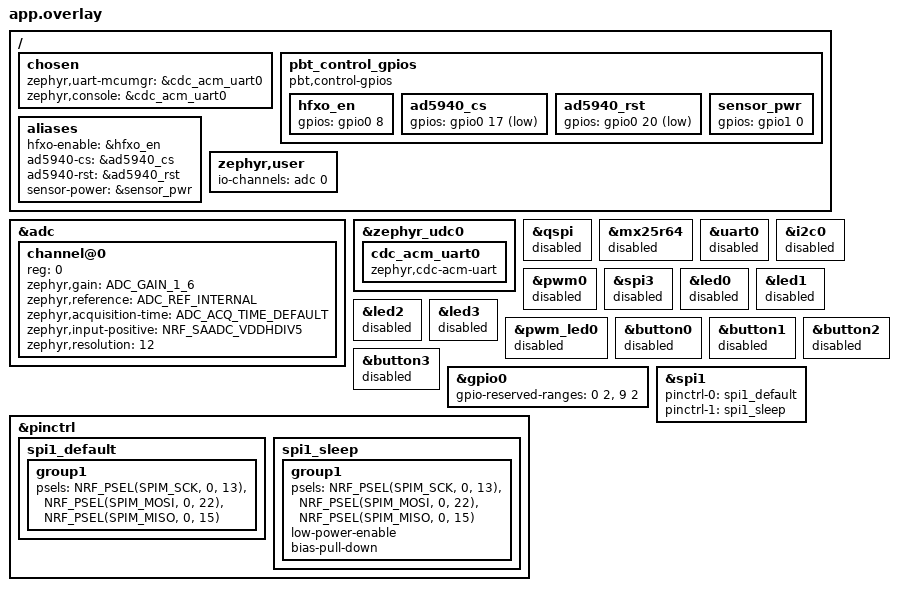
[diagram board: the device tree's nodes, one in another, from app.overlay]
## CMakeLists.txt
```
cmake_minimum_required(VERSION 3.20.0)
find_package(Zephyr REQUIRED HINTS $ENV{ZEPHYR_BASE})
project(nfc_ble_auth)

target_sources(app PRIVATE
    src/main.c
    src/nfc_handler.c
    src/ble_manager.c
    src/gatt_service.c
    src/power_manager.c
    src/ad5940.c
    src/ad5940_port.c
    src/RampTest.c
    src/CV.c
    src/ad5940_lp.c
    src/CA.c
    src/DPV.c
)
target_include_directories(app PRIVATE src)
# CHIPSEL_594X sélectionne les chemins de code AD5940 (pas ADuCM355)
target_compile_definitions(app PRIVATE CHIPSEL_594X)
```

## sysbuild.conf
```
# Active MCUboot via sysbuild
SB_CONFIG_BOOTLOADER_MCUBOOT=y
```

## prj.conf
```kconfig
# ── Bluetooth ─────────────────────────────────────────────────────────────
CONFIG_BT=y
CONFIG_BT_PERIPHERAL=y
CONFIG_BT_DEVICE_NAME="NFC_AUTH_DK"
CONFIG_BT_SMP=y
CONFIG_BT_SMP_SC_PAIR_ONLY=y
CONFIG_BT_CTLR_SDC_LLPM=n   
CONFIG_BT_BONDABLE=y
CONFIG_BT_SETTINGS=y
CONFIG_BT_MAX_PAIRED=1
CONFIG_BT_MAX_CONN=1

# ── Horloge basse fréquence de la carte ───────────────────────────────────
# U5 est un OV-7604-C7 actif (sortie CMOS 32,768 kHz, ±20 ppm) connecté à XL1,
# et non un quartz entre XL1/XL2. Le mode XTAL hérité de la cible DK est faux.
CONFIG_CLOCK_CONTROL_NRF_K32SRC_EXT_FULL_SWING=y
CONFIG_CLOCK_CONTROL_NRF_K32SRC_20PPM=y

# ── NFC T2T (pas T4T — le code utilise nfc_t2t_lib.h) ────────────────────
CONFIG_NFC_T2T_NRFXLIB=y          # ← T2T, pas T4T
CONFIG_NFC_NDEF=y
CONFIG_NFC_NDEF_MSG=y
CONFIG_NFC_NDEF_RECORD=y
CONFIG_NFC_NDEF_LE_OOB_REC=y

# ── Flash + NVS ───────────────────────────────────────────────────────────
# Le driver Flash interne nRF doit être activé en premier
CONFIG_FLASH=y
CONFIG_SOC_FLASH_NRF=y             # ← active le driver Flash nRF52840
CONFIG_FLASH_PAGE_LAYOUT=y         # dépend de SOC_FLASH_NRF → OK maintenant
CONFIG_FLASH_MAP=y
CONFIG_NVS=y
CONFIG_SETTINGS=y
CONFIG_SETTINGS_NVS=y              # backend NVS pour les settings BLE (liaisons)

# ── Logging ───────────────────────────────────────────────────────────────
CONFIG_LOG=y
CONFIG_LOG_DEFAULT_LEVEL=3

# ── Gestion d'alimentation ────────────────────────────────────────────────
# Pas de CONFIG_PM=y : HAS_PM n'est pas sélectionné pour nRF52840 en Zephyr 4.x.
# Le scheduler Zephyr fait automatiquement WFI (System ON sleep) quand inactif —
# comportement identique à ce qu'on cherche.

# ── ADC (SAADC) pour lecture du rail VDDH/VDD ───────────────────────────
CONFIG_ADC=y

# ── SPI (AD5940) ──────────────────────────────────────────────────────────
CONFIG_SPI=y
CONFIG_PINCTRL=y
CONFIG_PM_DEVICE=y

# MCUboot
CONFIG_BOOTLOADER_MCUBOOT=y
CONFIG_MCUBOOT_IMG_MANAGER=y

# USB (API NCS 3.x)
CONFIG_USB_DEVICE_STACK_NEXT=y
CONFIG_UART_LINE_CTRL=y

# mcumgr core + dépendances complètes
CONFIG_MCUMGR=y
CONFIG_NET_BUF=y
CONFIG_ZCBOR=y
CONFIG_CRC=y
CONFIG_BASE64=y

# mcumgr groups (noms NCS 3.x)
CONFIG_MCUMGR_GRP_OS=y
CONFIG_MCUMGR_GRP_IMG=y

CONFIG_MCUMGR_TRANSPORT_UDP=n
CONFIG_USBD_CDC_ACM_CLASS=y
# DFU USB mcumgr sur le port CDC. Le pilotage CV passe par un groupe SMP custom
# sur CE MÊME canal (multiplexé par mcumgr) → 1 seul port, pas de conflit.
CONFIG_MCUMGR_TRANSPORT_UART=y
CONFIG_UART_LINE_CTRL=y

# Le canal SMP doit rester PROPRE : on ne met AUCUN texte console/log sur l'UART
# (ça corromprait les trames SMP). Console + logs partent sur RTT (J-Link).
CONFIG_UART_CONSOLE=n
CONFIG_LOG_BACKEND_UART=n

# Pool de buffers du contrôleur USB : 1024 o (défaut) trop petit (échec
# "udc: Failed to allocate net_buf"). On l'agrandit.
CONFIG_UDC_BUF_POOL_SIZE=16384
CONFIG_UDC_BUF_COUNT=32

CONFIG_REBOOT=y

CONFIG_USE_SEGGER_RTT=y
CONFIG_RTT_CONSOLE=y
CONFIG_LOG_BACKEND_RTT=y

# Image manager + dépendances explicites
CONFIG_STREAM_FLASH=y
CONFIG_FLASH_MAP=y
CONFIG_FLASH=y
CONFIG_IMG_MANAGER=y

CONFIG_MPU_ALLOW_FLASH_WRITE=y

CONFIG_MCUMGR_TRANSPORT_UART_ASYNC=n

CONFIG_MCUMGR_TRANSPORT_NETBUF_SIZE=4096
CONFIG_MCUMGR_TRANSPORT_WORKQUEUE_STACK_SIZE=8192
CONFIG_MCUMGR_TRANSPORT_NETBUF_COUNT=6
# STATUS contient un diagnostic détaillé directement dans la map principale ;
# DATA contient des listes. Dimensionner explicitement les sauvegardes zcbor.
CONFIG_MCUMGR_SMP_CBOR_MAX_MAIN_MAP_ENTRIES=77
CONFIG_MCUMGR_SMP_CBOR_MAX_ENCODING_LEVELS=1

# Une commande START de CV par défaut occupe 131 octets après encodage
# SMP-over-UART (base64 + marqueur). La valeur par défaut de 128 rejette donc
# la commande avant même l'appel du handler.
CONFIG_UART_MCUMGR_RX_BUF_SIZE=256
CONFIG_UART_MCUMGR_RX_BUF_COUNT=2
```

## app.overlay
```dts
#include <dt-bindings/adc/nrf-adc.h>

/ {
    chosen {
        zephyr,uart-mcumgr = &cdc_acm_uart0;
        zephyr,console     = &cdc_acm_uart0;
    };

    /*
     * GPIO P0.08 : OE de l'oscillateur actif 32 MHz OSC1 du nRF52840.
     * Il doit rester HIGH : USB/BLE peut demander HFCLK à tout instant ; le
     * forcer LOW fige le CPU/USBD alors que le port COM reste encore énuméré.
     * Référencé via l'alias "hfxo-enable" dans power_manager.c.
     */
    /* Nœud volontairement neutre : ces lignes sont des commandes de carte,
     * pas des LED. Elles ne doivent jamais être revendiquées par le pilote LED. */
    pbt_control_gpios {
        compatible = "pbt,control-gpios";
        hfxo_en: hfxo_en {
            gpios = <&gpio0 8 GPIO_ACTIVE_HIGH>;
        };
        /* AD5940 : CS P0.17 (actif bas), RST P0.20 (actif bas), alim P1.00 */
        ad5940_cs: ad5940_cs {
            gpios = <&gpio0 17 GPIO_ACTIVE_LOW>;
        };
        ad5940_rst: ad5940_rst {
            gpios = <&gpio0 20 GPIO_ACTIVE_LOW>;
        };
        sensor_pwr: sensor_pwr {
            gpios = <&gpio1 0 GPIO_ACTIVE_HIGH>;
        };
    };

    aliases {
        hfxo-enable  = &hfxo_en;
        ad5940-cs    = &ad5940_cs;
        ad5940-rst   = &ad5940_rst;
        sensor-power = &sensor_pwr;
    };

    /*
     * Canal ADC pour lecture du rail VDDH/VDD de cette carte.
     * Utilise VDDHDIV5 (entrée interne nRF52840 = VDDH/5) — aucun pin requis.
     */
    zephyr,user {
        io-channels = <&adc 0>;
    };
};

/* Canal logique SAADC 0 : entrée interne VDDHDIV5, aucun GPIO. */
&adc {
    status = "okay";
    #address-cells = <1>;
    #size-cells = <0>;

    channel@0 {
        reg = <0>;
        zephyr,gain             = "ADC_GAIN_1_6";
        zephyr,reference        = "ADC_REF_INTERNAL";
        zephyr,acquisition-time = <ADC_ACQ_TIME_DEFAULT>;
        zephyr,input-positive   = <NRF_SAADC_VDDHDIV5>; /* VDDH/5 interne — aucun pin requis */
        zephyr,resolution       = <12>;
    };
};

&zephyr_udc0 {
    status = "okay";
    /* Port unique SMP : DFU mcumgr + commandes/données de mesure. Logs sur RTT. */
    cdc_acm_uart0: cdc_acm_uart0 {
        compatible = "zephyr,cdc-acm-uart";
    };
};

/*
 * Le binaire utilise encore la cible Zephyr nrf52840dk/nrf52840, mais le PCB
 * PBT n'embarque aucun des périphériques Arduino/QSPI de la DK. Les laisser
 * actifs crée de vrais conflits de broches : le QSPI de la DK revendique
 * notamment P0.17/P0.20/P0.22 (CS/RESET/MOSI de l'AD5940) et l'UART0 P0.08
 * (commande de l'oscillateur externe). Le DFU passe par l'USB natif ci-dessus
 * et ne dépend d'aucun de ces blocs.
 */
&qspi  { status = "disabled"; };
&mx25r64 { status = "disabled"; };
&uart0 { status = "disabled"; };
&i2c0  { status = "disabled"; };
&pwm0  { status = "disabled"; };
&spi3  { status = "disabled"; };

/* Nœuds d'E/S purement DK : certains partagent SCLK/MISO de l'AD5940. */
&led0     { status = "disabled"; };
&led1     { status = "disabled"; };
&led2     { status = "disabled"; };
&led3     { status = "disabled"; };
&pwm_led0 { status = "disabled"; };
&button0  { status = "disabled"; };
&button1  { status = "disabled"; };
&button2  { status = "disabled"; };
&button3  { status = "disabled"; };

&gpio0 {
    /* Garder uniquement XL1/XL2 et NFC1/NFC2 réservés. */
    gpio-reserved-ranges = <0 2>, <9 2>;
};

/* ── SPI1 : AD5940 ──────────────────────────────────────────────────────── */
/* SCLK=P0.13  MOSI=P0.22  MISO=P0.15  CS=P0.17 (GPIO manuel, actif bas) */
&pinctrl {
    spi1_default: spi1_default {
        group1 {
            psels = <NRF_PSEL(SPIM_SCK,  0, 13)>,
                    <NRF_PSEL(SPIM_MOSI, 0, 22)>,
                    <NRF_PSEL(SPIM_MISO, 0, 15)>;
        };
    };
    spi1_sleep: spi1_sleep {
        group1 {
            psels = <NRF_PSEL(SPIM_SCK,  0, 13)>,
                    <NRF_PSEL(SPIM_MOSI, 0, 22)>,
                    <NRF_PSEL(SPIM_MISO, 0, 15)>;
            low-power-enable;
            bias-pull-down;
        };
    };
};

&spi1 {
    status = "okay";
    pinctrl-0 = <&spi1_default>;
    pinctrl-1 = <&spi1_sleep>;
    pinctrl-names = "default", "sleep";
};
```

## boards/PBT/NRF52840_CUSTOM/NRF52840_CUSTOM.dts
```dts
/dts-v1/;

#include <nordic/nrf52840_qiaa.dtsi>
#include "NRF52840_CUSTOM-pinctrl.dtsi"

/ {
	model = "PBT custom board";
	compatible = "PBT,NRF52840-CUSTOM";

	chosen {
		zephyr,sram = &sram0;
		zephyr,flash = &flash0;
		zephyr,code-partition = &slot0_partition;
	};
};

&flash0 {
	partitions {
		compatible = "fixed-partitions";
		#address-cells = <1>;
		#size-cells = <1>;

		boot_partition: partition@0 {
			label = "mcuboot";
			reg = <0x0 DT_SIZE_K(80)>;
		};

		slot0_partition: partition@14000 {
			label = "image-0";
			reg = <0x14000 DT_SIZE_K(456)>;
		};

		slot1_partition: partition@86000 {
			label = "image-1";
			reg = <0x86000 DT_SIZE_K(456)>;
		};

		storage_partition: partition@f8000 {
			label = "storage";
			reg = <0xf8000 DT_SIZE_K(32)>;
		};
	};
};
```

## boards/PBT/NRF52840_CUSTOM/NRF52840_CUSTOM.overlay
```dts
&zephyr_udc0 {
    status = "okay";
    cdc_acm_uart0: cdc_acm_uart0 {
        compatible = "zephyr,cdc-acm-uart";
    };
};
```

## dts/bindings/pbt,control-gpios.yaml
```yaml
description: GPIO command lines owned directly by the ParisBioTek application

compatible: "pbt,control-gpios"

child-binding:
  description: One application-owned GPIO command line

  properties:
    gpios:
      type: phandle-array
      required: true
```

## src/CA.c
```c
#include "CA.h"
#include "ad5940_lp.h"

#include <zephyr/kernel.h>
#include <zephyr/logging/log.h>
#include <math.h>

LOG_MODULE_REGISTER(ca, LOG_LEVEL_INF);

static ca_params_t s_p = {
    .pot_mv      = 500.0f,
    .vzero_mv    = 1300.0f,
    .duration_ms = 10000,
    .interval_ms = 100,
};
static cv_point_cb_t s_cb;
static int32_t       s_peak_na;

void CA_SetPointCallback(cv_point_cb_t cb) { s_cb = cb; }

void CA_GetParams(ca_params_t *out) { if (out) *out = s_p; }

int CA_SetParams(const ca_params_t *in)
{
    if (!in) return -1;
    if (!isfinite(in->pot_mv) || !isfinite(in->vzero_mv)) return -1;
    if (in->duration_ms < 100u  || in->duration_ms > 600000u) return -1;
    if (in->interval_ms < 5u    || in->interval_ms > 10000u)  return -1;
    if (in->interval_ms > in->duration_ms)                    return -1;
    if (in->duration_ms / in->interval_ms > CV_MAX_TOTAL_POINTS) return -1;
    if (lp_validate_potential_mv(in->vzero_mv, in->pot_mv) != 0) return -1;
    s_p = *in;
    LOG_INF("CA params : E=%d mV  Vzero=%d mV  durée=%u ms  intervalle=%u ms",
            (int)s_p.pot_mv, (int)s_p.vzero_mv,
            (unsigned)s_p.duration_ms, (unsigned)s_p.interval_ms);
    return 0;
}

int32_t CA_GetPeakCurrentNa(void) { return s_peak_na; }

static bool ca_wait_or_stop(uint32_t delay_ms, measurement_stop_cb_t stop_cb)
{
    while (delay_ms > 0u) {
        if (stop_cb && stop_cb()) return true;
        uint32_t slice_ms = (delay_ms > 20u) ? 20u : delay_ms;
        k_sleep(K_MSEC(slice_ms));
        delay_ms -= slice_ms;
    }
    return stop_cb && stop_cb();
}

int CA_Run(float lfosc_hz, uint32_t rtia_ohm,
           measurement_stop_cb_t stop_cb)
{
    ca_params_t p = s_p;
    s_peak_na = 0;

    if (stop_cb && stop_cb()) {
        return MEAS_RUN_STOPPED;
    }

    if (lp_setup(lfosc_hz, rtia_ohm) != 0) {
        return -1;
    }

    if (stop_cb && stop_cb()) {
        lp_teardown();
        return MEAS_RUN_STOPPED;
    }

    if (lp_set_potential_mv(p.vzero_mv, p.pot_mv) != 0) {
        lp_teardown();
        return -1;
    }
    if (ca_wait_or_stop(50u, stop_cb)) {     /* établissement de la cellule */
        lp_teardown();
        return MEAS_RUN_STOPPED;
    }

    uint32_t n = p.duration_ms / p.interval_ms;
    if (n == 0) n = 1;

    int64_t t0   = k_uptime_get();
    float   peak = 0.0f;

    for (uint32_t k = 0; k < n; k++) {
        int64_t target = t0 + (int64_t)k * p.interval_ms;
        int64_t now    = k_uptime_get();
        if (target > now) {
            if (ca_wait_or_stop((uint32_t)(target - now), stop_cb)) {
                s_peak_na = (int32_t)(peak * 1000.0f);
                lp_teardown();
                LOG_INF("CA interrompue par l'utilisateur apres %u point(s)",
                        (unsigned)k);
                return MEAS_RUN_STOPPED;
            }
        }
        if (stop_cb && stop_cb()) {
            s_peak_na = (int32_t)(peak * 1000.0f);
            lp_teardown();
            return MEAS_RUN_STOPPED;
        }
        float i_ua = lp_read_current_ua();
        if (!isfinite(i_ua)) {
            lp_teardown();
            return -1;
        }
        if (fabsf(i_ua) > peak) peak = fabsf(i_ua);

        uint32_t t_ms = (uint32_t)(k_uptime_get() - t0);
        if (s_cb) s_cb(k, (float)t_ms, i_ua);   /* X = temps (ms) */
    }

    s_peak_na = (int32_t)(peak * 1000.0f);
    lp_teardown();
    LOG_INF("CA terminée — %u points, pic=%d nA", (unsigned)n, s_peak_na);
    return 0;
}
```

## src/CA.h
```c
#ifndef CA_H_
#define CA_H_

#include <stdint.h>
#include "ad5940.h"
#include "methods.h"
#include "CV.h"          /* cv_point_cb_t (callback commun aux méthodes) */

/* Chronoampérométrie (i–t) : potentiel fixe, courant échantillonné dans le temps.
 * Logiciel-timé (LPDAC + lectures ADC ponctuelles via ad5940_lp). X = temps (ms). */
typedef struct {
    float    pot_mv;       /* potentiel appliqué (mV, électrode de travail) */
    float    vzero_mv;     /* point de polarisation Vzero (mV)              */
    uint32_t duration_ms;  /* durée totale de la mesure (ms)                */
    uint32_t interval_ms;  /* période d'échantillonnage (ms)                */
} ca_params_t;

void    CA_SetPointCallback(cv_point_cb_t cb);
void    CA_GetParams(ca_params_t *out);
int     CA_SetParams(const ca_params_t *in);   /* 0 si OK, <0 si hors plage */

/* Lance la chronoampérométrie (bloquant). rtia_ohm = gamme (ohms, >0).
 * Retour : 0 si le run est complet, MEAS_RUN_STOPPED si l'utilisateur l'a
 * interrompu, valeur négative en cas d'erreur technique. */
int     CA_Run(float lfosc_hz, uint32_t rtia_ohm,
               measurement_stop_cb_t stop_cb);

/* Pic de courant absolu du dernier run (nA). */
int32_t CA_GetPeakCurrentNa(void);

#endif /* CA_H_ */
```

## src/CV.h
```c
#ifndef _CV_H_
#define _CV_H_

#include <stdint.h>
#include "ad5940.h"
#include "methods.h"

/* ═══════════════════════════════════════════════════════════════════════════
   PARAMÈTRES UTILISATEUR
   ═══════════════════════════════════════════════════════════════════════════ */
#define CV_START_VOLT_MV        -1000.0f
#define CV_PEAK_VOLT_MV         +1000.0f
#define CV_VZERO_MV              1300.0f

#define CV_STEP_NUMBER            800
#define CV_CYCLE_COUNT              1
#define CV_DURATION_MS          24000
#define CV_SAMPLE_DELAY_MS        7.0f
#define CV_SETTLE_MS              2000u
#define CV_SETTLE_MAX_MS         60000u

/* Must stay in sync with the point-transfer buffer in main.c. */
#define CV_MAX_TOTAL_POINTS       4000u

#define CV_RTIA_SEL             LPTIARTIA_4K
#define CV_ADC_PGA_GAIN         ADCPGA_1P5

#define CV_RCAL_OHM             100.0f
/* AD5940_ADCCode2Volt() attend des volts, pas des millivolts. */
#define CV_ADC_REF_V              1.820f

/* Forçage du RTIA en ohms : si > 0, la calibration RTIA est ignorée et cette
 * valeur est utilisée pour convertir le courant. À utiliser quand la
 * calibration (qui dépend de la RCAL externe = CV_RCAL_OHM) est fausse.
 * Mettre 0 pour calibrer normalement.
 * Valeur empirique mesurée avec une résistance étalon de 10 kΩ : ~4600 Ω. */
#define CV_RTIA_OVERRIDE_OHM    0

/* ═══════════════════════════════════════════════════════════════════════════
   API PUBLIQUE
   ═══════════════════════════════════════════════════════════════════════════ */

AD5940Err CV_Init(float lfosc_hz);
AD5940Err CV_Start(void);
/* Retourne immédiatement toute erreur ISR/séquenceur afin que l'appelant ne
 * transforme pas la cause initiale en simple timeout générique. */
AD5940Err CV_Service(void);
void      CV_Abort(void);
int       CV_IsFinished(void);
AD5940Err CV_Restart(void);

/* Courant de pic mesuré lors du dernier cycle, en nanoampères (nA).
 * Valeur absolue maximale parmi tous les points du cycle. */
int32_t CV_GetPeakCurrentNa(void);

/* Résistance estimée du dernier cycle (Ω), pente V/I par moindres carrés
 * passant par l'origine. Pertinent pour tester une simple résistance.
 * Retourne 0 si pas assez de points. */
float CV_GetResistanceOhm(void);

/* Callback appelé pour CHAQUE point traité pendant le cycle CV.
 * @param index       index de l'échantillon dans le cycle (0..StepNumber)
 * @param volt_mv     tension appliquée à cet échantillon (mV)
 * @param current_ua  courant mesuré (µA)
 */
typedef void (*cv_point_cb_t)(uint32_t index, float volt_mv, float current_ua);

/* Enregistre (ou retire avec NULL) le callback par point. */
void CV_SetPointCallback(cv_point_cb_t cb);

/* ═══════════════════════════════════════════════════════════════════════════
   PARAMÈTRES DE BALAYAGE RÉGLABLES AU RUNTIME
   Initialisés aux valeurs CV_* ci-dessus ; surchargeables via CV_SetParams()
   (commande "SET" reçue sur le serial). Les gains matériels (RTIA, PGA, RCAL,
   Vref ADC) restent fixes/calibrés et ne sont PAS exposés.
   ═══════════════════════════════════════════════════════════════════════════ */
typedef struct {
    float    start_mv;        /* tension de départ du balayage (mV)        */
    float    peak_mv;         /* tension de sommet du balayage (mV)        */
    float    vzero_mv;        /* tension de polarisation Vzero (mV)        */
    uint32_t step_number;     /* nombre de pas PAR cycle (pair, >= 2)      */
    uint32_t cycle_count;     /* nombre de cycles successifs (>= 1)        */
    uint32_t duration_ms;     /* durée d'UN cycle (ms)                     */
    float    sample_delay_ms; /* délai d'échantillon par pas (ms)          */
    uint32_t settle_ms;       /* maintien a start_mv avant le 1er point */
} cv_params_t;

/* Copie les paramètres courants (réglables) dans *out. */
void CV_GetParams(cv_params_t *out);

/* Valide puis applique de nouveaux paramètres. Retourne 0 si OK, <0 si une
 * valeur est hors plage (dans ce cas les paramètres ne sont pas modifiés).
 * La prise d'effet est au prochain CV_Init() : un cycle en cours n'est pas
 * perturbé. */
int CV_SetParams(const cv_params_t *in);

/* Durée totale (ms) du run EN COURS, tous cycles compris (instantané pris
 * au CV_Init), pour le timeout. La stabilisation initiale n'est pas incluse. */
uint32_t CV_GetActiveDurationMs(void);

/* Geometry of the run currently prepared by CV_Init(). `step_number` remains
 * the number of points in one elementary cycle. */
uint32_t CV_GetActiveStepNumber(void);
uint32_t CV_GetActiveCycleCount(void);
uint32_t CV_GetActiveTotalPoints(void);

/* ═══════════════════════════════════════════════════════════════════════════
   GAMME DE MESURE (RTIA) — réglable au runtime + autorange
   Le RTIA fixe la fenêtre de courant : I_max ≈ ~0,9 V / RTIA.
   ═══════════════════════════════════════════════════════════════════════════ */

/* Règle le RTIA (ohms) : la valeur de table la plus proche est retenue.
 * ohm == 0  → active l'autorange (choix automatique de la gamme).
 * Retourne l'ohm effectivement retenu (0 si autorange). */
int CV_SetRtia(uint32_t ohm);

/* RTIA nominal courant (ohms), ou 0 si autorange actif (pour le réglage). */
uint32_t CV_GetRtiaOhm(void);

/* RTIA nominal effectivement sélectionné (ohms), même en autorange (pour le
 * rapport après choix). */
uint32_t CV_GetActiveRtiaOhm(void);

/* 1 si l'autorange est actif, 0 sinon. */
int CV_GetAutorange(void);

/* RTIA réellement calibré au dernier CV_Init (ohms). */
uint32_t CV_GetCalibratedRtiaOhm(void);

/* Renvoie la sélection matérielle LPTIARTIA_* de la valeur de table la plus
 * proche de `ohm` ; *ohm_out (si non NULL) reçoit l'ohm nominal correspondant.
 * Utilisé par les autres méthodes (ad5940_lp) pour partager la même table RTIA. */
uint32_t CV_RtiaSelNearest(uint32_t ohm, uint32_t *ohm_out);

/* Sélection automatique de gamme : lance des balayages de sonde rapides pour
 * choisir le RTIA. À appeler après l'init AD5940 et AVANT le CV_Init du vrai
 * cycle. Ne fait rien si l'autorange n'est pas actif. */
int CV_Autorange(float lfosc_hz, measurement_stop_cb_t stop_cb);

/* Applique le potentiel initial directement au LPDAC apres CV_Init(), sans
 * lancer le WUPT ni produire d'echantillon. L'appelant maintient ensuite ce
 * potentiel pendant settle_ms avant CV_Start(). */
AD5940Err CV_ApplyStartPotential(void);

/* Stabilisation configuree pour le run fige par le dernier CV_Init(). */
uint32_t CV_GetActiveSettleMs(void);

#endif /* _CV_H_ */
```

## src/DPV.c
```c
#include "DPV.h"
#include "ad5940_lp.h"

#include <zephyr/kernel.h>
#include <zephyr/logging/log.h>
#include <math.h>

LOG_MODULE_REGISTER(dpv, LOG_LEVEL_INF);

static dpv_params_t s_p = {
    .start_mv   = -600.0f,
    .end_mv     =  600.0f,
    .estep_mv   =    5.0f,
    .epulse_mv  =   50.0f,
    .tpulse_ms  =   50,
    .tperiod_ms =  200,
    .vzero_mv   = 1300.0f,
};
static cv_point_cb_t s_cb;
static int32_t       s_peak_na;

void DPV_SetPointCallback(cv_point_cb_t cb) { s_cb = cb; }

void DPV_GetParams(dpv_params_t *out) { if (out) *out = s_p; }

int DPV_SetParams(const dpv_params_t *in)
{
    if (!in) return -1;
    if (!isfinite(in->start_mv) || !isfinite(in->end_mv) ||
        !isfinite(in->estep_mv) || !isfinite(in->epulse_mv) ||
        !isfinite(in->vzero_mv))                              return -1;
    if (in->end_mv == in->start_mv)                        return -1;
    if (in->estep_mv <= 0.0f || in->estep_mv > 200.0f)     return -1;
    if (in->epulse_mv == 0.0f || fabsf(in->epulse_mv) > 500.0f) return -1;
    if (in->tpulse_ms < 5u || in->tpulse_ms > 5000u)       return -1;
    if (in->tperiod_ms <= in->tpulse_ms || in->tperiod_ms > 20000u) return -1;
    if ((uint32_t)(fabsf(in->end_mv - in->start_mv) /
                   fabsf(in->estep_mv)) + 1u > CV_MAX_TOTAL_POINTS) return -1;
    if (lp_validate_potential_mv(in->vzero_mv, in->start_mv) != 0 ||
        lp_validate_potential_mv(in->vzero_mv, in->end_mv) != 0 ||
        lp_validate_potential_mv(in->vzero_mv, in->start_mv + in->epulse_mv) != 0 ||
        lp_validate_potential_mv(in->vzero_mv, in->end_mv + in->epulse_mv) != 0) return -1;
    s_p = *in;
    LOG_INF("DPV params : %d→%d mV  pas=%d  pulse=%d mV  tp=%u ms  T=%u ms",
            (int)s_p.start_mv, (int)s_p.end_mv, (int)s_p.estep_mv,
            (int)s_p.epulse_mv, (unsigned)s_p.tpulse_ms, (unsigned)s_p.tperiod_ms);
    return 0;
}

int32_t DPV_GetPeakCurrentNa(void) { return s_peak_na; }

static bool dpv_wait_or_stop(uint32_t delay_ms, measurement_stop_cb_t stop_cb)
{
    while (delay_ms > 0u) {
        if (stop_cb && stop_cb()) return true;
        uint32_t slice_ms = (delay_ms > 20u) ? 20u : delay_ms;
        k_sleep(K_MSEC(slice_ms));
        delay_ms -= slice_ms;
    }
    return stop_cb && stop_cb();
}

int DPV_Run(float lfosc_hz, uint32_t rtia_ohm,
            measurement_stop_cb_t stop_cb)
{
    dpv_params_t p = s_p;
    s_peak_na = 0;

    if (stop_cb && stop_cb()) {
        return MEAS_RUN_STOPPED;
    }

    if (lp_setup(lfosc_hz, rtia_ohm) != 0) {
        return -1;
    }

    if (stop_cb && stop_cb()) {
        lp_teardown();
        return MEAS_RUN_STOPPED;
    }

    float    dir     = (p.end_mv >= p.start_mv) ? 1.0f : -1.0f;
    float    step    = dir * fabsf(p.estep_mv);
    uint32_t nsteps  = (uint32_t)(fabsf(p.end_mv - p.start_mv) / fabsf(p.estep_mv)) + 1u;
    uint32_t tbase   = p.tperiod_ms - p.tpulse_ms;
    float    peak    = 0.0f;

    if (lp_set_potential_mv(p.vzero_mv, p.start_mv) != 0) {
        lp_teardown();
        return -1;
    }
    if (dpv_wait_or_stop(50u, stop_cb)) {    /* établissement de la cellule */
        lp_teardown();
        return MEAS_RUN_STOPPED;
    }

    for (uint32_t k = 0; k < nsteps; k++) {
        float e_base = p.start_mv + step * (float)k;

        /* Niveau de base : on mesure I1 en fin de palier. */
        if (lp_set_potential_mv(p.vzero_mv, e_base) != 0) {
            lp_teardown();
            return -1;
        }
        if (dpv_wait_or_stop(tbase, stop_cb)) {
            s_peak_na = (int32_t)(peak * 1000.0f);
            lp_teardown();
            LOG_INF("DPV interrompue par l'utilisateur apres %u point(s)",
                    (unsigned)k);
            return MEAS_RUN_STOPPED;
        }
        float i1 = lp_read_current_ua();
        if (stop_cb && stop_cb()) {
            s_peak_na = (int32_t)(peak * 1000.0f);
            lp_teardown();
            LOG_INF("DPV interrompue par l'utilisateur apres %u point(s)",
                    (unsigned)k);
            return MEAS_RUN_STOPPED;
        }

        /* Impulsion : on mesure I2 en fin d'impulsion. */
        if (lp_set_potential_mv(p.vzero_mv, e_base + p.epulse_mv) != 0) {
            lp_teardown();
            return -1;
        }
        if (dpv_wait_or_stop(p.tpulse_ms, stop_cb)) {
            s_peak_na = (int32_t)(peak * 1000.0f);
            lp_teardown();
            LOG_INF("DPV interrompue par l'utilisateur apres %u point(s)",
                    (unsigned)k);
            return MEAS_RUN_STOPPED;
        }
        float i2 = lp_read_current_ua();

        if (!isfinite(i1) || !isfinite(i2)) {
            lp_teardown();
            return -1;
        }

        float di = i2 - i1;
        if (fabsf(di) > peak) peak = fabsf(di);
        if (s_cb) s_cb(k, e_base, di);       /* X = tension base (mV), Y = ΔI */
    }

    s_peak_na = (int32_t)(peak * 1000.0f);
    lp_teardown();
    LOG_INF("DPV terminée — %u points, pic ΔI=%d nA", (unsigned)nsteps, s_peak_na);
    return 0;
}
```

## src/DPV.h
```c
#ifndef DPV_H_
#define DPV_H_

#include <stdint.h>
#include "ad5940.h"
#include "methods.h"
#include "CV.h"          /* cv_point_cb_t (callback commun aux méthodes) */

/* Voltampérométrie à impulsions différentielles (DPV) : escalier start→end par
 * pas estep ; à chaque marche, un niveau de base puis une impulsion epulse.
 * On enregistre ΔI = I(fin d'impulsion) − I(fin de base) au potentiel de base.
 * Logiciel-timé (LPDAC + lectures ADC via ad5940_lp). X = tension (mV), Y = ΔI. */
typedef struct {
    float    start_mv;     /* potentiel de départ (mV)                */
    float    end_mv;       /* potentiel de fin (mV)                   */
    float    estep_mv;     /* hauteur de marche (mV, > 0)             */
    float    epulse_mv;    /* amplitude d'impulsion (mV)              */
    uint32_t tpulse_ms;    /* durée d'impulsion (ms)                  */
    uint32_t tperiod_ms;   /* période par marche (ms, > tpulse_ms)    */
    float    vzero_mv;     /* point de polarisation Vzero (mV)        */
} dpv_params_t;

void    DPV_SetPointCallback(cv_point_cb_t cb);
void    DPV_GetParams(dpv_params_t *out);
int     DPV_SetParams(const dpv_params_t *in);   /* 0 si OK, <0 si hors plage */

/* Lance la DPV (bloquant). rtia_ohm = gamme (ohms, >0).
 * Retour : 0 si le run est complet, MEAS_RUN_STOPPED si l'utilisateur l'a
 * interrompu, valeur négative en cas d'erreur technique. */
int     DPV_Run(float lfosc_hz, uint32_t rtia_ohm,
                measurement_stop_cb_t stop_cb);

/* Pic de |ΔI| du dernier run (nA). */
int32_t DPV_GetPeakCurrentNa(void);

#endif /* DPV_H_ */
```

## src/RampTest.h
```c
/*!
 *****************************************************************************
 @file:    RampTest.h
 @author:  Neo Xu – Analog Devices Inc.
 @brief:   Ramp Test header file (Cyclic Voltammetry).
 *
 * Source original : https://github.com/analogdevicesinc/ad5940-examples
 * Adapté pour ESP-IDF / ESP32.
 *
 * Copyright (c) 2017-2019 Analog Devices, Inc. All Rights Reserved.
 * This software is proprietary to Analog Devices, Inc. and its licensors.
 *****************************************************************************/
#ifndef _RAMPTEST_H_
#define _RAMPTEST_H_

#include "ad5940.h"
#include <stdio.h>
#include "string.h"
#include "math.h"

/* Ne pas modifier ces paramètres internes */
#define ALIGIN_VOLT2LSB     0               /* 1 = aligner chaque pas au LSB du DAC */
#define DAC12BITVOLT_1LSB   (2200.0f/4095)  /* mV par LSB (12 bits) */
#define DAC6BITVOLT_1LSB    (DAC12BITVOLT_1LSB*64)  /* mV par LSB (6 bits) */

/**
 * @brief Structure de configuration du test Ramp (Voltampérométrie Cyclique).
 */
typedef struct
{
    /* Paramètres communs à toutes les applications */
    BoolFlag  bParaChanged;         /**< Forcer la regénération des séquences */
    uint32_t  SeqStartAddr;         /**< Adresse de départ des séquences en SRAM AD5940 */
    uint32_t  MaxSeqLen;            /**< Longueur max des séquences */
    uint32_t  SeqStartAddrCal;      /**< Non utilisé pour Ramp */
    uint32_t  MaxSeqLenCal;         /**< Non utilisé pour Ramp */

    /* Paramètres temporels */
    float     LFOSCClkFreq;         /**< Fréquence LFOSC mesurée (Hz), typiquement ~32 kHz */
    float     SysClkFreq;           /**< Fréquence horloge système (Hz) */
    float     AdcClkFreq;           /**< Fréquence horloge ADC (Hz) */
    float     RcalVal;              /**< Valeur du Rcal en Ohm */
    float     ADCRefVolt;           /**< Tension de référence ADC réelle en V */
    BoolFlag  bTestFinished;        /**< Indicateur de fin de test */

    /* Paramètres du signal rampe (Voltampérométrie Cyclique) */
    float     RampStartVolt;        /**< Tension de départ en mV */
    float     RampPeakVolt;         /**< Tension crête (max/min) en mV */
    float     VzeroStart;           /**< Tension Vzero initiale en mV */
    float     VzeroPeak;            /**< Tension Vzero au pic en mV */
    uint32_t  StepNumber;           /**< Nombre total de pas du run (≤ 4095) */
    uint32_t  StepsPerCycle;        /**< Nombre de pas d'un cycle élémentaire */
    uint32_t  CycleCount;           /**< Nombre de cycles élémentaires */
    uint32_t  RampDuration;         /**< Durée totale du run en ms */

    /* Chemin de réception */
    float     SampleDelay;          /**< Délai entre MAJ DAC et déclenchement ADC (ms) */
    uint32_t  LPTIARtiaSel;        /**< Sélection Rtia interne (LPTIARTIA_xxx) */
    uint32_t  LPTIARloadSel;       /**< Sélection Rload (LPTIARLOAD_xxx) */
    float     ExternalRtiaValue;    /**< Valeur Rtia externe en Ohm (si LPTIARTIA_OPEN) */
    uint32_t  AdcPgaGain;           /**< Gain PGA ADC */
    uint8_t   ADCSinc3Osr;         /**< Sur-échantillonnage filtre SINC3 */

    /* Numérique */
    uint32_t  FifoThresh;           /**< Seuil FIFO */

    /* Variables privées internes */
    BoolFlag      RAMPInited;
    fImpPol_Type  RtiaValue;
    SEQInfo_Type  InitSeqInfo;
    SEQInfo_Type  ADCSeqInfo;
    BoolFlag      bFirstDACSeq;
    SEQInfo_Type  DACSeqInfo;
    uint32_t      CurrStepPos;
    float         DACCodePerStep;
    float         CurrRampCode;
    uint32_t      CurrVzeroCode;
    BoolFlag      bDACCodeInc;
    BoolFlag      StopRequired;
    enum _RampState {
        RAMP_STATE0 = 0,
        RAMP_STATE1,
        RAMP_STATE2,
        RAMP_STATE3,
        RAMP_STATE4,
        RAMP_STOP
    } RampState;
    BoolFlag  bRampOneDir;          /**< Rampe unidirectionnelle (LSV) si bTRUE */
} AppRAMPCfg_Type;

/* Instantané de diagnostic du moteur ping-pong. Il permet de distinguer une
 * perte de CUSTOMINT0, une faute FIFO et une erreur de régénération du bloc. */
typedef struct
{
    uint32_t service_calls;
    uint32_t custom_irq_count;
    uint32_t refill_count;
    uint32_t blocks_generated;
    uint32_t steps_per_block;
    uint32_t steps_remaining;
    uint32_t last_block_steps;
    uint32_t last_intc0;
    uint32_t last_intc1;
    /* Une lecture INTC0 peut exceptionnellement renvoyer la derniere valeur
     * du registre SEQSLPLOCK (0xA47E5) si l'AFE se rendort entre le reveil SPI
     * et la lecture. Ces champs rendent le rejet/retry visible dans STATUS. */
    uint32_t last_rejected_intc0;
    uint32_t last_rejected_intc1;
    uint32_t intc_retry_count;
    uint32_t stale_intc_count;
    uint32_t fatal_recheck_count;
    uint32_t unconfirmed_fatal_count;
    uint32_t latched_flags;
    uint32_t fatal_flags;
    /* Instantane des registres du sequenceur, capture uniquement lorsqu'une
     * faute fatale est confirmee par deux lectures successives. */
    uint32_t seq_timeout;
    uint32_t seq_count;
    uint32_t seq_con;
    uint32_t seq0_info;
    uint32_t seq1_info;
    uint32_t seq2_info;
    uint32_t seq3_info;
    /* SEQ_STOP terminates Init by clearing SEQEN. This remains a reliable
     * completion proof when the ENDSEQ interrupt is not observed. */
    uint32_t init_endseq_missing;
    uint32_t init_wait_polls;
    uint32_t init_direct_fallback;
    uint32_t last_fifo_count;
    uint32_t max_fifo_count;
    int32_t  last_error;
} AppRAMPDiag_Type;

/* Commandes de contrôle */
#define APPCTRL_START       0
#define APPCTRL_STOPNOW     1
#define APPCTRL_STOPSYNC    2
#define APPCTRL_SHUTDOWN    3

/* API publique */
AD5940Err AppRAMPInit(uint32_t *pBuffer, uint32_t BufferSize);
AD5940Err AppRAMPGetCfg(void *pCfg);
void      AppRAMPGetDiag(AppRAMPDiag_Type *pDiag);
void      AppRAMPResetDiag(void);
AD5940Err AppRAMPISR(void *pBuff, uint32_t *pCount);
AD5940Err AppRAMPCtrl(uint32_t Command, void *pPara);

#endif /* _RAMPTEST_H_ */
```

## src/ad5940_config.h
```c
/**
 * @file ad5940_config.h
 * @brief Configuration pour la librairie AD5940
 * Définit les options de compilation requises
 */

#ifndef AD5940_CONFIG_H
#define AD5940_CONFIG_H

// Configuration pour AD5940 (pas ADuCM355)
#define CHIPSEL_594X

#endif // AD5940_CONFIG_H
```

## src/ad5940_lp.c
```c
#include "ad5940_lp.h"
#include "CV.h"          /* CV_RtiaSelNearest, CV_RCAL_OHM, CV_ADC_REF_V, CV_ADC_PGA_GAIN */
#include "RampTest.h"    /* DAC12BITVOLT_1LSB, DAC6BITVOLT_1LSB */

#include <zephyr/logging/log.h>
#include <math.h>

LOG_MODULE_REGISTER(ad5940_lp, LOG_LEVEL_INF);

#define LP_ADC_REF_V    CV_ADC_REF_V
#define LP_PGA          CV_ADC_PGA_GAIN
#define LP_RCAL_OHM     CV_RCAL_OHM

static float    s_rtia_mag = 0.0f;      /* RTIA calibré (ohms)          */
static uint32_t s_rtia_nom = 0;         /* RTIA nominal retenu (ohms)   */
static uint32_t s_rtia_sel = LPTIARTIA_4K;
static lp_potential_state_t s_potential;

/* ── Config de référence (identique RampTest.c) ─────────────────────────── */
static void lp_ref_cfg(void)
{
    AFERefCfg_Type aferef_cfg;
    aferef_cfg.HpBandgapEn   = bTRUE;
    aferef_cfg.Hp1V1BuffEn   = bTRUE;
    aferef_cfg.Hp1V8BuffEn   = bTRUE;
    aferef_cfg.Disc1V1Cap    = bFALSE;
    aferef_cfg.Disc1V8Cap    = bFALSE;
    aferef_cfg.Hp1V8ThemBuff = bFALSE;
    aferef_cfg.Hp1V8Ilimit   = bFALSE;
    aferef_cfg.Lp1V1BuffEn   = bFALSE;
    aferef_cfg.Lp1V8BuffEn   = bFALSE;
    aferef_cfg.LpBandgapEn   = bTRUE;
    aferef_cfg.LpRefBufEn    = bTRUE;
    aferef_cfg.LpRefBoostEn  = bFALSE;
    AD5940_REFCfgS(&aferef_cfg);
}

/* ── Boucle LP : LPTIA0 + LPDAC0 pour une ampérométrie DC ──────────────── */
static void lp_loop_cfg(void)
{
    LPLoopCfg_Type lploop_cfg;

    lploop_cfg.LpAmpCfg.LpAmpSel    = LPAMP0;
    lploop_cfg.LpAmpCfg.LpAmpPwrMod = LPAMPPWR_BOOST3;
    lploop_cfg.LpAmpCfg.LpPaPwrEn   = bTRUE;
    lploop_cfg.LpAmpCfg.LpTiaPwrEn  = bTRUE;
    lploop_cfg.LpAmpCfg.LpTiaRf     = LPTIARF_20K;
    lploop_cfg.LpAmpCfg.LpTiaRload  = LPTIARLOAD_SHORT;
    lploop_cfg.LpAmpCfg.LpTiaRtia   = s_rtia_sel;
    /* AD5940, table "Normal dc current measurement" : 0x302c.
     * L'ancienne topologie 0x0034 est celle d'une rampe/pulse et ne reliait
     * pas correctement le potentiostat/TIA à la cellule maintenue en DC. */
    lploop_cfg.LpAmpCfg.LpTiaSW     = LPTIASW(13) | LPTIASW(12) |
                                        LPTIASW(5)  | LPTIASW(3)  | LPTIASW(2);

    lploop_cfg.LpDacCfg.LpdacSel      = LPDAC0;
    lploop_cfg.LpDacCfg.DacData12Bit  = 0x800;
    lploop_cfg.LpDacCfg.DacData6Bit   = 0;
    lploop_cfg.LpDacCfg.DataRst       = bFALSE;
    lploop_cfg.LpDacCfg.LpDacSW       = LPDACSW_VBIAS2LPPA | LPDACSW_VZERO2LPTIA |
                                        LPDACSW_VBIAS2PIN;
    lploop_cfg.LpDacCfg.LpDacRef      = LPDACREF_2P5;
    lploop_cfg.LpDacCfg.LpDacSrc      = LPDACSRC_MMR;
    lploop_cfg.LpDacCfg.LpDacVbiasMux = LPDACVBIAS_12BIT;
    lploop_cfg.LpDacCfg.LpDacVzeroMux = LPDACVZERO_6BIT;
    lploop_cfg.LpDacCfg.PowerEn       = bTRUE;
    AD5940_LPLoopCfgS(&lploop_cfg);
}

/* ── Chaîne ADC : mux LPTIA0, PGA, filtres (identique RampTest.c) ───────── */
static void lp_dsp_cfg(void)
{
    DSPCfg_Type dsp_cfg;
    AD5940_StructInit(&dsp_cfg, sizeof(dsp_cfg));
    dsp_cfg.ADCBaseCfg.ADCMuxN            = ADCMUXN_LPTIA0_N;
    dsp_cfg.ADCBaseCfg.ADCMuxP            = ADCMUXP_LPTIA0_P;
    dsp_cfg.ADCBaseCfg.ADCPga             = LP_PGA;
    dsp_cfg.ADCFilterCfg.ADCSinc3Osr      = ADCSINC3OSR_2;
    dsp_cfg.ADCFilterCfg.ADCRate          = ADCRATE_800KHZ;
    dsp_cfg.ADCFilterCfg.BpSinc3          = bFALSE;
    dsp_cfg.ADCFilterCfg.Sinc2NotchEnable = bTRUE;
    dsp_cfg.ADCFilterCfg.BpNotch          = bTRUE;    /* notch bypassé → SINC2 */
    dsp_cfg.ADCFilterCfg.ADCSinc2Osr      = ADCSINC2OSR_1067;
    dsp_cfg.ADCFilterCfg.ADCAvgNum        = ADCAVGNUM_2;
    AD5940_DSPCfgS(&dsp_cfg);
}

/* ── Calibration RTIA (identique CV : RCAL externe = CV_RCAL_OHM) ───────── */
static void lp_rtia_cal(void)
{
    if (s_rtia_sel == LPTIARTIA_OPEN) {
        s_rtia_mag = 20000.0f;
        return;
    }
    fImpPol_Type   cal;
    LPRTIACal_Type lprtia_cal;
    AD5940_StructInit(&lprtia_cal, sizeof(lprtia_cal));
    lprtia_cal.LpAmpSel     = LPAMP0;
    lprtia_cal.bPolarResult = bTRUE;
    lprtia_cal.AdcClkFreq   = 16000000.0f;
    lprtia_cal.SysClkFreq   = 16000000.0f;
    lprtia_cal.ADCSinc3Osr  = ADCSINC3OSR_4;
    lprtia_cal.ADCSinc2Osr  = ADCSINC2OSR_22;
    lprtia_cal.DftCfg.DftNum   = DFTNUM_2048;
    lprtia_cal.DftCfg.DftSrc   = DFTSRC_SINC2NOTCH;
    lprtia_cal.DftCfg.HanWinEn = bTRUE;
    lprtia_cal.fFreq        = 16000000.0f / 4 / 22 / 2048 * 3;
    lprtia_cal.fRcal        = LP_RCAL_OHM;
    lprtia_cal.LpTiaRtia    = s_rtia_sel;
    lprtia_cal.LpAmpPwrMod  = LPAMPPWR_NORM;
    lprtia_cal.bWithCtia    = bFALSE;
    AD5940_LPRtiaCal(&lprtia_cal, &cal);
    s_rtia_mag = cal.Magnitude;
}

int lp_setup(float lfosc_hz, uint32_t rtia_ohm)
{
    (void)lfosc_hz;

    s_rtia_sel = CV_RtiaSelNearest(rtia_ohm, &s_rtia_nom);

    if (AD5940_WakeUp(10) > 10) {
        LOG_ERR("LP: réveil AD5940 échoué");
        return -1;
    }
    AD5940_AFECtrlS(AFECTRL_ALL, bFALSE);

    lp_ref_cfg();
    lp_loop_cfg();
    lp_dsp_cfg();

    /* La cal reconfigure l'AFE (DFT, switches) : on la fait puis on ré-applique
     * la config de boucle/ADC de mesure. */
    lp_rtia_cal();
    if (s_rtia_mag <= 0.0f) {
        s_rtia_mag = (float)s_rtia_nom;   /* garde-fou si cal ratée */
    }
    lp_ref_cfg();
    lp_loop_cfg();
    lp_dsp_cfg();
    AD5940_AFEPwrBW(AFEPWR_LP, AFEBW_250KHZ);

    LOG_INF("LP setup : RTIA nominal=%u ohm, calibré=%d ohm",
            (unsigned)s_rtia_nom, (int)s_rtia_mag);
    return 0;
}

int lp_validate_potential_mv(float vzero_mv, float e_mv)
{
    if (!isfinite(vzero_mv) || !isfinite(e_mv)) return -1;
    if (vzero_mv < 200.0f ||
        vzero_mv > 200.0f + 63.0f * DAC6BITVOLT_1LSB) return -1;

    uint32_t VzeroCode = (uint32_t)((vzero_mv - 200.0f) / DAC6BITVOLT_1LSB + 0.5f);
    if (VzeroCode > 63) return -1;

    int32_t rampCode  = (int32_t)lroundf(e_mv / DAC12BITVOLT_1LSB);
    int32_t VbiasCode = (int32_t)(VzeroCode * 64) + rampCode;
    return (VbiasCode >= 0 && VbiasCode <= 4095) ? 0 : -1;
}

int lp_set_potential_mv(float vzero_mv, float e_mv)
{
    s_potential.e_mv     = (int32_t)lroundf(e_mv);
    s_potential.vzero_mv = (int32_t)lroundf(vzero_mv);
    s_potential.valid    = 0;
    s_potential.readback_ok = 0;
    s_potential.dac_register = 0;

    if (lp_validate_potential_mv(vzero_mv, e_mv) != 0) {
        LOG_WRN("LPDAC refuse : Vzero=%d mV, E=%d mV", (int)vzero_mv, (int)e_mv);
        return -1;
    }

    uint32_t VzeroCode = (uint32_t)((vzero_mv - 200.0f) / DAC6BITVOLT_1LSB + 0.5f);
    int32_t VbiasCode = (int32_t)(VzeroCode * 64) +
                        (int32_t)lroundf(e_mv / DAC12BITVOLT_1LSB);
    uint32_t written = ((uint32_t)VzeroCode << 12) | (uint32_t)VbiasCode;

    AD5940_WriteReg(REG_AFE_LPDACDAT0, written);
    s_potential.vzero_code = (uint8_t)VzeroCode;
    s_potential.vbias_code = (uint16_t)VbiasCode;
    s_potential.dac_register = AD5940_ReadReg(REG_AFE_LPDACDAT0) & 0x3ffffu;
    s_potential.valid = 1;
    s_potential.readback_ok = (s_potential.dac_register == written) ? 1u : 0u;
    if (!s_potential.readback_ok) {
        LOG_WRN("LPDAC lecture incohérente : écrit=0x%05x lu=0x%05x",
                (unsigned)written, (unsigned)s_potential.dac_register);
        return -1;
    }
    return 0;
}

void lp_get_potential_state(lp_potential_state_t *out)
{
    if (out) *out = s_potential;
}

float lp_read_current_ua(void)
{
    uint32_t code = 0;

    /* Deux conversions : la 1re « amorce » le filtre SINC2, on garde la 2de. */
    for (int k = 0; k < 2; k++) {
        AD5940_AFECtrlS(AFECTRL_ADCPWR, bTRUE);
        AD5940_Delay10us(25);                       /* ~250 µs power-up ADC */
        AD5940_INTCClrFlag(AFEINTSRC_SINC2RDY);
        AD5940_AFECtrlS(AFECTRL_ADCCNV | AFECTRL_SINC2NOTCH, bTRUE);

        BoolFlag ready = bFALSE;
        for (uint32_t guard = 0; guard < 2000u; guard++) { /* maximum ~20 ms */
            if (AD5940_INTCTestFlag(AFEINTC_1, AFEINTSRC_SINC2RDY) != bFALSE) {
                ready = bTRUE;
                break;
            }
            AD5940_Delay10us(1);
        }
        if (ready == bFALSE) {
            AD5940_AFECtrlS(AFECTRL_ADCCNV | AFECTRL_SINC2NOTCH | AFECTRL_ADCPWR, bFALSE);
            LOG_ERR("LP ADC : timeout SINC2RDY");
            return NAN;
        }
        AD5940_INTCClrFlag(AFEINTSRC_SINC2RDY);
        code = AD5940_ReadAfeResult(AFERESULT_SINC2) & 0xFFFF;
        AD5940_AFECtrlS(AFECTRL_ADCCNV | AFECTRL_SINC2NOTCH | AFECTRL_ADCPWR, bFALSE);
    }

    /* Même conversion que RampTest : courant en µA, RTIA calibré. */
    if (!(s_rtia_mag > 0.0f)) return NAN;
    float volt = -AD5940_ADCCode2Volt(code, LP_PGA, LP_ADC_REF_V);
    /* AD5940_ADCCode2Volt renvoie des volts : V / ohm = A, puis A -> µA. */
    return volt / s_rtia_mag * 1e6f;
}

uint32_t lp_rtia_nominal_ohm(void)    { return s_rtia_nom; }
uint32_t lp_rtia_calibrated_ohm(void) { return (uint32_t)(s_rtia_mag + 0.5f); }

void lp_teardown(void)
{
    AD5940_AFECtrlS(AFECTRL_ADCCNV | AFECTRL_SINC2NOTCH | AFECTRL_ADCPWR, bFALSE);
}
```
